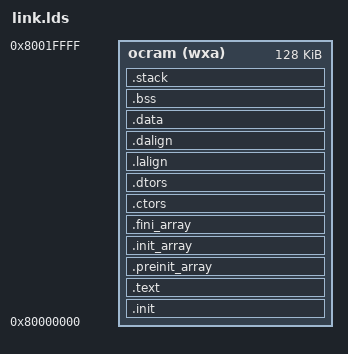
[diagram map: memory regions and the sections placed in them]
OUTPUT_ARCH( "riscv" )
ENTRY(_start)


MEMORY
{
 /* dram (wx) : ORIGIN = 0x00000000, LENGTH =  */
  ocram (wxa) : ORIGIN = 0x80000000, LENGTH = 128K
}

REGION_ALIAS("ROM", ocram)      /*all data and code put into ocram*/
REGION_ALIAS("RAM", ocram)
REGION_ALIAS("DATA_LMA", ocram)

SECTIONS
{
   __stack_size = DEFINED(__stack_size) ? __stack_size : 8K;

  .init           :
  {
    KEEP (*(SORT_NONE(.init)))
  } >ROM AT>ROM 

  .text           :
  {
    *(.text.unlikely .text.unlikely.*)
    *(.text.startup .text.startup.*)
    *(.text .text.*)
    *(.gnu.linkonce.t.*)
  } >ROM AT>ROM 

  . = ALIGN(4);

  PROVIDE (__etext = .);
  PROVIDE (_etext = .);
  PROVIDE (etext = .);

  .preinit_array  :
  {
    PROVIDE_HIDDEN (__preinit_array_start = .);
    KEEP (*(.preinit_array))
    PROVIDE_HIDDEN (__preinit_array_end = .);
  } >ROM AT>ROM 

  .init_array     :
  {
    PROVIDE_HIDDEN (__init_array_start = .);
    KEEP (*(SORT_BY_INIT_PRIORITY(.init_array.*) SORT_BY_INIT_PRIORITY(.ctors.*)))
    KEEP (*(.init_array EXCLUDE_FILE (*crtbegin.o *crtbegin?.o *crtend.o *crtend?.o ) .ctors))
    PROVIDE_HIDDEN (__init_array_end = .);
  } >ROM AT>ROM 

  .fini_array     :
  {
    PROVIDE_HIDDEN (__fini_array_start = .);
    KEEP (*(SORT_BY_INIT_PRIORITY(.fini_array.*) SORT_BY_INIT_PRIORITY(.dtors.*)))
    KEEP (*(.fini_array EXCLUDE_FILE (*crtbegin.o *crtbegin?.o *crtend.o *crtend?.o ) .dtors))
    PROVIDE_HIDDEN (__fini_array_end = .);
  } >ROM AT>ROM 

  .ctors          :
  {
    /* gcc uses crtbegin.o to find the start of
       the constructors, so we make sure it is
       first.  Because this is a wildcard, it
       doesn't matter if the user does not
       actually link against crtbegin.o; the
       linker won't look for a file to match a
       wildcard.  The wildcard also means that it
       doesn't matter which directory crtbegin.o
       is in.  */
    KEEP (*crtbegin.o(.ctors))
    KEEP (*crtbegin?.o(.ctors))
    /* We don't want to include the .ctor section from
       the crtend.o file until after the sorted ctors.
       The .ctor section from the crtend file contains the
       end of ctors marker and it must be last */
    KEEP (*(EXCLUDE_FILE (*crtend.o *crtend?.o ) .ctors))
    KEEP (*(SORT(.ctors.*)))
    KEEP (*(.ctors))
  } >ROM AT>ROM 

  .dtors          :
  {
    KEEP (*crtbegin.o(.dtors))
    KEEP (*crtbegin?.o(.dtors))
    KEEP (*(EXCLUDE_FILE (*crtend.o *crtend?.o ) .dtors))
    KEEP (*(SORT(.dtors.*)))
    KEEP (*(.dtors))
  } >ROM AT>ROM 

  .lalign         :
  {
    . = ALIGN(4);
    PROVIDE( _data_lma = . );
  } >ROM AT>ROM 

  .dalign         :
  {
    . = ALIGN(4);
    PROVIDE( _data = . );
  } >RAM AT>ROM 

  .data          :
  {
    *(.rdata)
    *(.rodata .rodata.*)
    *(.gnu.linkonce.r.*)
    *(.data .data.*)
    *(.gnu.linkonce.d.*)
    . = ALIGN(8);
    PROVIDE( __global_pointer$ = . + 0x800 );
    *(.sdata .sdata.*)
    *(.gnu.linkonce.s.*)
    . = ALIGN(8);
    *(.srodata.cst16)
    *(.srodata.cst8)
    *(.srodata.cst4)
    *(.srodata.cst2)
    *(.srodata .srodata.*)
  } >RAM AT>ROM 

  . = ALIGN(4);
  PROVIDE( _edata = . );
  PROVIDE( edata = . );

  PROVIDE( _fbss = . );
  PROVIDE( __bss_start = . );
  .bss            :
  {
    *(.sbss*)
    *(.gnu.linkonce.sb.*)
    *(.bss .bss.*)
    *(.gnu.linkonce.b.*)
    *(COMMON)
    . = ALIGN(4);
  } >RAM AT>RAM 

  . = ALIGN(8);
  PROVIDE( _end = . );
  PROVIDE( end = . );

  .stack ORIGIN(RAM) + LENGTH(RAM) - __stack_size :
  {
    PROVIDE( _heap_end = . );
    . = __stack_size;
    PROVIDE( _sp = . );
    __freertos_irq_stack_top = .;
  } >RAM AT>RAM

}
